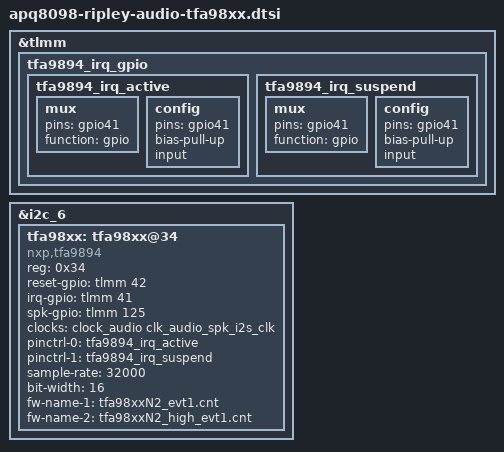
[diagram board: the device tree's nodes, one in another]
/* Copyright (c) 2018, Facebook Inc. All rights reserved.
 *
 * This program is free software; you can redistribute it and/or modify
 * it under the terms of the GNU General Public License version 2 and
 * only version 2 as published by the Free Software Foundation.
 *
 * This program is distributed in the hope that it will be useful,
 * but WITHOUT ANY WARRANTY; without even the implied warranty of
 * MERCHANTABILITY or FITNESS FOR A PARTICULAR PURPOSE.  See the
 * GNU General Public License for more details.
 */
#include <dt-bindings/gpio/gpio.h>

/* Render CODEC */

&tlmm {
	tfa9894_irq_gpio {
		tfa9894_irq_active: tfa9894_irq_active {
			mux {
				pins = "gpio41";
				function = "gpio";
			};
			config {
				pins = "gpio41";
				bias-pull-up;
				input;
			};
		};

		tfa9894_irq_suspend: tfa9894_irq_suspend {
			mux {
				pins = "gpio41";
				function = "gpio";
			};
			config {
				pins = "gpio41";
				bias-pull-up;
				input;
			};
		};
	};
};


&i2c_6 {
	tfa98xx: tfa98xx@34 {
		compatible = "nxp,tfa9894";
		reg = <0x34>;
		reset-gpio = <&tlmm 42 GPIO_ACTIVE_HIGH>;
		irq-gpio = <&tlmm 41 0>;
		spk-gpio = <&tlmm 125 0>;
		clock-names = "mclk";
		clocks = <&clock_audio clk_audio_spk_i2s_clk>;

		pinctrl-names = "default", "sleep";
		pinctrl-0 = <&tfa9894_irq_active>;
		pinctrl-1 = <&tfa9894_irq_suspend>;
		sample-rate = <32000>;
		bit-width = <16>;
		fw-name-1 = "tfa98xxN2_evt1.cnt";
		fw-name-2 = "tfa98xxN2_high_evt1.cnt";
	};
};
